# PN74xxAU register map
File version: 2
CPU: CM0 r0p0, little endian, no MPU, no FPU, 2 interrupt priority bits
Registers are 32-bit, read-write, reset 0x0 unless marked. A register's access mark holds for its fields unless they carry their own. Offsets are from the block's base; [hi:lo] are bit positions; {n}, {i} and the like mark numbered series.

## I2CM — I2C Master
Base 0x40030000
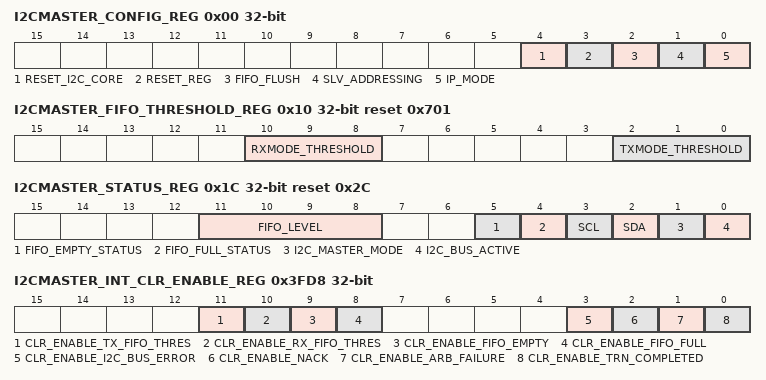
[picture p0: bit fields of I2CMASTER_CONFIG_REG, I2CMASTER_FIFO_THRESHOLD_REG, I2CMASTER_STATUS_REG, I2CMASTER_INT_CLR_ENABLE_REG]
0x00 I2CMASTER_CONFIG_REG — I2C Master config register (RW)
  [4] RESET_I2C_CORE wo — Set Only (Pulse) Register Bit Field to Reset the I2C Core Block.
  [3] RESET_REG wo — Set Only (Pulse) Register Bit Field to Reset Selected Registers of I2C Master
  [2] FIFO_FLUSH wo — Set Only (Pulse) Register Bit Field to flush the FIFO irrespective of I2C Master Mode of operation
  [1] SLV_ADDRESSING — I2C Slave 7/10 bit address selection
  [0] IP_MODE — I2C Master Mode selection
0x04 I2CMASTER_BAUDRATE_REG reset 0xF4 — I2C Master baudrate sellection register (RW)
  [7:0] BAUDRATE — BAUDRATE bit field is used for the I2C Serial Clock Frequency calculation.
0x08 I2CMASTER_SDA_HOLD_REG reset 0x9 — I2C Master SDA Hold Time Config register (RW)
  [4:0] SDA_HOLD — SDA Hold time
0x0C I2CMASTER_I2C_ADDRESS_REG reset 0x2A — I2C Master Slave address register (RW)
  [9:0] SLAVE_ADDRESS — I2C Slave 7 bit or 10 bit address
0x10 I2CMASTER_FIFO_THRESHOLD_REG reset 0x701 — I2C Master FIFO threshold register (RW)
  [10:8] RXMODE_THRESHOLD — FIFO Threshold level for Interrupt Request generation when I2C Master is configured for I2C Reception mode.
  [2:0] TXMODE_THRESHOLD — FIFO Threshold level for Interrupt Request generation when I2C Master is configured for I2C Transmission mode.
0x14 I2CMASTER_BYTECOUNT_CONFIG_REG — I2C Master Byte Count Config register (RW)
  [9:0] BYTE_COUNT_CONFIG — This register bit field is used to configure the number of byte to be Transmitted or Received. A maximum of 1023 byte can be transmitted or received in a frame.
0x18 I2CMASTER_BYTECOUNT_STATUS_REG ro — I2C Master Byte Count Status register (R)
  [9:0] BYTE_COUNT_STATUS — This register bit field is used to provide the status of number of byte currently Transmitted or Received. A maximum of 1023 byte can be transmitted or received in a frame.
0x1C I2CMASTER_STATUS_REG ro reset 0x2C — I2C Master Status register (R)
  [11:8] FIFO_LEVEL — This register bit field is used to provide the status of number of byte currently Transmitted or Received. A maximum of 1023 byte can be transmitted or received in a frame.
  [5] FIFO_EMPTY_STATUS — Indicates the FIFO empty condition irrespective of I2C Master Mode of operation
  [4] FIFO_FULL_STATUS — Indicates the FIFO full condition irrespective of I2C Master Mode of operation
  [3] SCL — Current Status of scl_a line
  [2] SDA — Current Status of sda_a line
  [1] I2C_MASTER_MODE — I2C Mode of operation. Status f rom the IP_MODE bit field of CONFIG_REG register
  [0] I2C_BUS_ACTIVE — Indicates I2C Transmission or Reception is On-going
0x20 I2CMASTER_CONTROL_REG wo — I2C Master Control register (W)
  [0] I2C_ENABLE — Enable I2C Transmission or Reception
{0x3C+4i} I2CMASTER_TXDATA{i}_REG wo (i=1..4) — I2C Master TX Data register (W)
  [31:0] TX_DATA{i} — Data to be transmitted
{0x4C+4i} I2CMASTER_RXDATA{i}_REG ro (i=1..4) — I2C Master RX Data register (R)
  [31:0] RX_DATA{i} — Data received
0x3FD8 I2CMASTER_INT_CLR_ENABLE_REG wo — I2C Master interrupt clear register
  [11] CLR_ENABLE_TX_FIFO_THRES — Writing 1 to this register does clear the corresponding IRQ ENABLE flag
  [10] CLR_ENABLE_RX_FIFO_THRES — Writing 1 to this register does clear the corresponding IRQ ENABLE flag
  [9] CLR_ENABLE_FIFO_EMPTY — Writing 1 to this register does clear the corresponding IRQ ENABLE flag
  [8] CLR_ENABLE_FIFO_FULL — Writing 1 to this register does clear the corresponding IRQ ENABLE flag
  [3] CLR_ENABLE_I2C_BUS_ERROR — Writing 1 to this register does clear the corresponding IRQ ENABLE flag
  [2] CLR_ENABLE_NACK — Writing 1 to this register does clear the corresponding IRQ ENABLE flag
  [1] CLR_ENABLE_ARB_FAILURE — Writing 1 to this register does clear the corresponding IRQ ENABLE flag
  [0] CLR_ENABLE_TRN_COMPLETED — Writing 1 to this register does clear the corresponding IRQ ENABLE flag
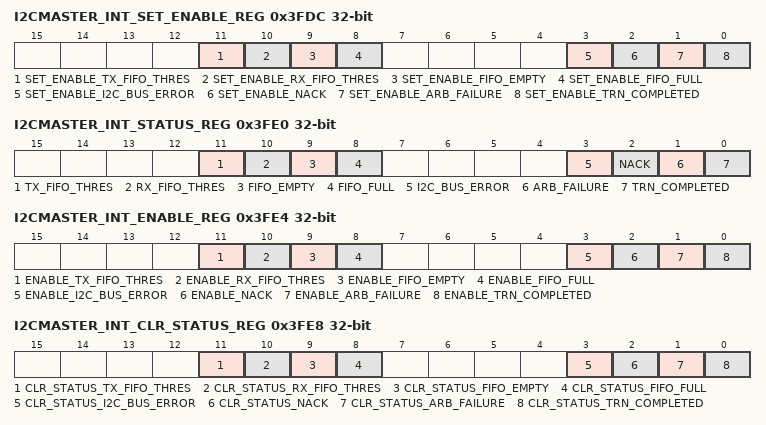
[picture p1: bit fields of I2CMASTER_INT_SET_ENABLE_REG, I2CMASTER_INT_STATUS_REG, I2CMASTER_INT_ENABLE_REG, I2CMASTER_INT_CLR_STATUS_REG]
0x3FDC I2CMASTER_INT_SET_ENABLE_REG wo — I2C Master interrupt enable register
  [11] SET_ENABLE_TX_FIFO_THRES — Writing 1 to this register does set the corresponding IRQ ENABLE flag
  [10] SET_ENABLE_RX_FIFO_THRES — Writing 1 to this register does set the corresponding IRQ ENABLE flag
  [9] SET_ENABLE_FIFO_EMPTY — Writing 1 to this register does set the corresponding IRQ ENABLE flag
  [8] SET_ENABLE_FIFO_FULL — Writing 1 to this register does set the corresponding IRQ ENABLE flag
  [3] SET_ENABLE_I2C_BUS_ERROR — Writing 1 to this register does set the corresponding IRQ ENABLE flag
  [2] SET_ENABLE_NACK — Writing 1 to this register does set the corresponding IRQ ENABLE flag
  [1] SET_ENABLE_ARB_FAILURE — Writing 1 to this register does set the corresponding IRQ ENABLE flag
  [0] SET_ENABLE_TRN_COMPLETED — Writing 1 to this register does set the corresponding IRQ ENABLE flag
0x3FE0 I2CMASTER_INT_STATUS_REG ro — I2C Master interrupt register
  [11] TX_FIFO_THRES — Indicates that the FIFO threshold is reached while I2C transmission is on-going
  [10] RX_FIFO_THRES — Indicates that the FIFO threshold is reached while I2C reception is on-going
  [9] FIFO_EMPTY — Indicates that the FIFO empty condition is reached while I2C transmission is on-going
  [8] FIFO_FULL — Indicates that the FIFO full condition is reached while I2C reception is on-going
  [3] I2C_BUS_ERROR — Indicates an I2C bus error occurred
  [2] NACK — Indicates an I2C slave didnt acknowledge the I2C master request
  [1] ARB_FAILURE — Indicates an I2C master arbitration failure
  [0] TRN_COMPLETED — Indicates an I2C master completed the I2C transmission or I2C reception
0x3FE4 I2CMASTER_INT_ENABLE_REG ro — I2C Master interrupt enable register
  [11] ENABLE_TX_FIFO_THRES — If this bit is 1 the corresponding IRQ can propergate to the CPUs IRQ controller
  [10] ENABLE_RX_FIFO_THRES — If this bit is 1 the corresponding IRQ can propergate to the CPUs IRQ controller
  [9] ENABLE_FIFO_EMPTY — If this bit is 1 the corresponding IRQ can propergate to the CPUs IRQ controller
  [8] ENABLE_FIFO_FULL — If this bit is 1 the corresponding IRQ can propergate to the CPUs IRQ controller
  [3] ENABLE_I2C_BUS_ERROR — If this bit is 1 the corresponding IRQ can propergate to the CPUs IRQ controller
  [2] ENABLE_NACK — If this bit is 1 the corresponding IRQ can propergate to the CPUs IRQ controller
  [1] ENABLE_ARB_FAILURE — If this bit is 1 the corresponding IRQ can propergate to the CPUs IRQ controller
  [0] ENABLE_TRN_COMPLETED — If this bit is 1 the corresponding IRQ can propergate to the CPUs IRQ controller
0x3FE8 I2CMASTER_INT_CLR_STATUS_REG wo — I2C Master interrupt status clear register
  [11] CLR_STATUS_TX_FIFO_THRES — Writing 1 to this register does clear the corresponding IRQ STATUS flag
  [10] CLR_STATUS_RX_FIFO_THRES — Writing 1 to this register does clear the corresponding IRQ STATUS flag
  [9] CLR_STATUS_FIFO_EMPTY — Writing 1 to this register does clear the corresponding IRQ STATUS flag
  [8] CLR_STATUS_FIFO_FULL — Writing 1 to this register does clear the corresponding IRQ STATUS flag
  [3] CLR_STATUS_I2C_BUS_ERROR — Writing 1 to this register does clear the corresponding IRQ STATUS flag
  [2] CLR_STATUS_NACK — Writing 1 to this register does clear the corresponding IRQ STATUS flag
  [1] CLR_STATUS_ARB_FAILURE — Writing 1 to this register does clear the corresponding IRQ STATUS flag
  [0] CLR_STATUS_TRN_COMPLETED — Writing 1 to this register does clear the corresponding IRQ STATUS flag
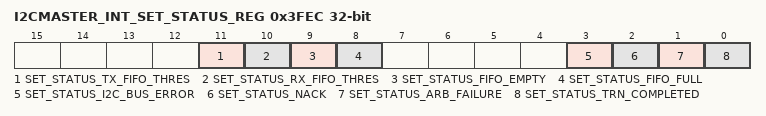
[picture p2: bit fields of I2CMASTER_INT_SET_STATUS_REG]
0x3FEC I2CMASTER_INT_SET_STATUS_REG wo — I2C Master interrupt status set register
  [11] SET_STATUS_TX_FIFO_THRES — Writing 1 to this register does set the corresponding IRQ STATUS flag
  [10] SET_STATUS_RX_FIFO_THRES — Writing 1 to this register does set the corresponding IRQ STATUS flag
  [9] SET_STATUS_FIFO_EMPTY — Writing 1 to this register does set the corresponding IRQ STATUS flag
  [8] SET_STATUS_FIFO_FULL — Writing 1 to this register does set the corresponding IRQ STATUS flag
  [3] SET_STATUS_I2C_BUS_ERROR — Writing 1 to this register does set the corresponding IRQ STATUS flag
  [2] SET_STATUS_NACK — Writing 1 to this register does set the corresponding IRQ STATUS flag
  [1] SET_STATUS_ARB_FAILURE — Writing 1 to this register does set the corresponding IRQ STATUS flag
  [0] SET_STATUS_TRN_COMPLETED — Writing 1 to this register does set the corresponding IRQ STATUS flag
